# ipro7 register map
Vendor: intelpro; Series: BTBLE
CPU: ipro7, little endian
Registers are 32-bit, read-write, reset 0x0 unless marked. A register's access mark holds for its fields unless they carry their own. Offsets are from the block's base; [hi:lo] are bit positions; {n}, {i} and the like mark numbered series.

## M154_AES
Base 0x3C001000
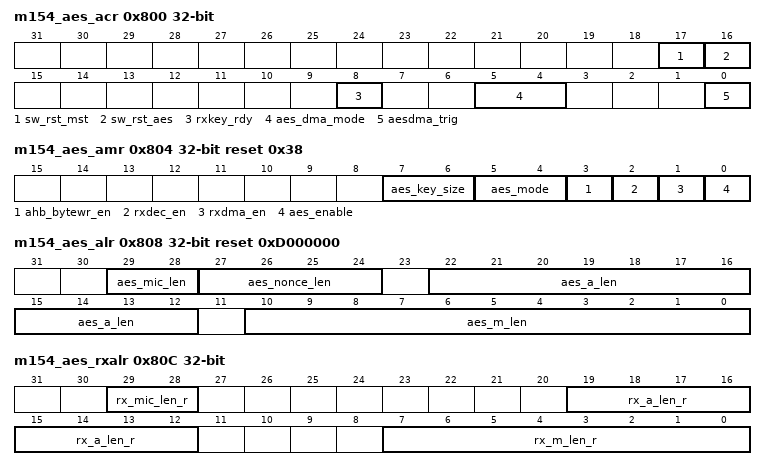
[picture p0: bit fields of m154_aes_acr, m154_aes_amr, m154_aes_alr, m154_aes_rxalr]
0x800 m154_aes_acr — AES control
  [17] sw_rst_mst — reset DDT master engine
  [16] sw_rst_aes — reset AES engine
  [8] rxkey_rdy — Validate key materials after key lookup complete
  [5:4] aes_dma_mode — 0 : FW mode encryption 1 : FW mode decryption 2 : HW mode TX DMA with encryption 3 : HW mode TX DMA without encryption
  [0] aesdma_trig — AES start
0x804 m154_aes_amr reset 0x38 — AES mode
  [7:6] aes_key_size — 0 : AES-128 1 : AES-192 2 : AES-256
  [5:4] aes_mode — 0 : AES Bypass mode : Bypass mode 1 : AES-CTR mode : Counter mode 2 : AES-CBC-MAC mode : Cipher Block Chaining Message Authentication Code mode 3 : AES-CCM mode : Counter with CBC-MAC
  [3] ahb_bytewr_en — Enable byte-write function
  [2] rxdec_en — Enable RX decryption function
  [1] rxdma_en — Enable RX DMA function
  [0] aes_enable — Enable AES and DMA state machine and clock.
0x808 m154_aes_alr reset 0xD000000 — AES length
  [29:28] aes_mic_len — AES Len = 4 / 8 / 16 / 12 bytes. Set 0 for AES Bypass mode.
  [27:24] aes_nonce_len — Nonce length (Byte) for CMAC/CCM mode. Value 11~14. Set 0 for AES Bypass mode.
  [22:12] aes_a_len — Additional authentication data length (Byte) or length of MPDU without FCS in AES Bypass mode
  [10:0] aes_m_len — Message length (Byte). Set 0 for CMAC mode and Bypass mode.
0x80C m154_aes_rxalr (reset mask 0xCFF00F00) — AES RX length
  [29:28] rx_mic_len_r ro — AES RX Len = 4 / 8 / 16 / 12 bytes. Valid in RX mode. Nonce length is always 13 bytes for CTR/CMAC/CCM mode
  [19:12] rx_a_len_r ro — The total length in byte of the additional authentication data, valid in RX mode
  [7:0] rx_m_len_r ro — The total length in byte of the message, valid in RX mode
0x810 m154_aes_aasar — AES a data source address
  [31:0] aes_asa — The source address of the Additional Authentication Data (a data) to be processed
0x814 m154_aes_amsar — AES m data source address
  [31:0] aes_msa — The source address of the encrypted or decrypted Message (m data)
0x818 m154_aes_amdar — AES m data destination address
  [31:0] aes_mda — The destination address of the encrypted or decrypted Message (c data)
0x81C m154_aes_rxaadar — AES RX a data destination address
  [31:0] aes_rxada — The destination address of the Additional Authentication Data (a data) to be processed in RX mode
0x820 m154_aes_rxamdar — AES RX m data destination address
  [31:0] aes_rxmda — The destination address of the decrypted Message (m data) in RX mode
0x830 m154_aes_anr0 — AES nonce
  [31:0] anr0 — Nonce field : Source Address({anr1[31:0], anr0[31:0]}), Frame Counter(anr2[31:0]), Security Level(anr3[7:0]) {anr2[23:0], anr1[31:0], anr0[31:0]} @aes_nonce_len=11 {anr2[31:0], anr1[31:0], anr0[31:0]} @aes_nonce_len=12 {anr3[7:0], anr2[31:0], anr1[31:0], anr0[31:0]} @aes_nonce_len=13 {anr3[15:0], anr2[31:0], anr1[31:0], anr0[31:0]} @aes_nonce_len=14
0x834 m154_aes_anr1
0x838 m154_aes_anr2
0x83C m154_aes_anr3
  [15:0] anr3
0x840 m154_aes_akr0 — AES key
  [31:0] akr0 — Key field {akr3, akr2, akr1, akr0} @AES-128 {akr5, akr4, akr3, akr2, akr1, akr0} @AES-192 {akr7, akr6, akr5, akr4, akr3, akr2, akr1, akr0} @AES-256
{0x840+4i} m154_aes_akr{i} (i=1..7)
0x860 m154_aes_amicr0 reset not defined — AES mic
  [31:0] amicr0 ro — Calculated MIC for CMAC/CCM, {amicr3, amicr2, amicr1, amicr0} depend on aes_mic_len
{0x860+4i} m154_aes_amicr{i} reset not defined (i=1..3)
  [31:0] amicr{i} ro
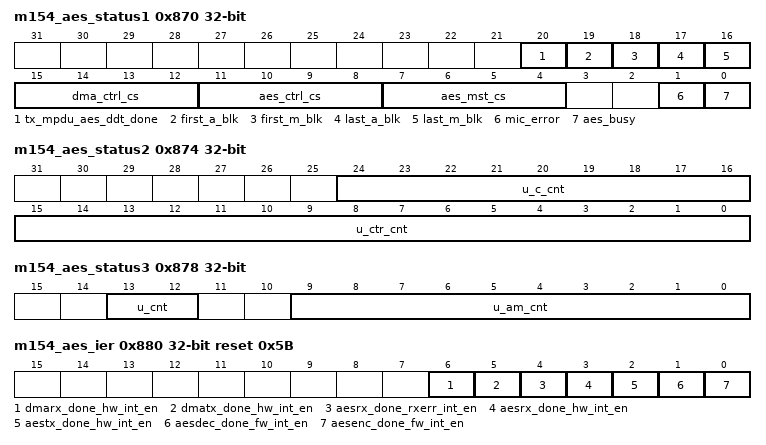
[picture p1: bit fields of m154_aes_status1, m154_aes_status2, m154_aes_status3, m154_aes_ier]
0x870 m154_aes_status1 (reset mask 0xFFE0000C) — AES status 1
  [20] tx_mpdu_aes_ddt_done ro
  [19] first_a_blk ro
  [18] first_m_blk ro
  [17] last_a_blk ro
  [16] last_m_blk ro
  [15:12] dma_ctrl_cs ro
  [11:8] aes_ctrl_cs ro
  [7:4] aes_mst_cs ro
  [1] mic_error ro — It means the MIC has been verified and checked passed
  [0] aes_busy ro — AES are busy processing
0x874 m154_aes_status2 (reset mask 0xFE000000) — AES status 2
  [24:16] u_c_cnt ro, [15:0] u_ctr_cnt ro
0x878 m154_aes_status3 (reset mask 0xFFFFCC00) — AES status 3
  [13:12] u_cnt ro, [9:0] u_am_cnt ro
0x880 m154_aes_ier reset 0x5B — Interrupt enable
  [6] dmarx_done_hw_int_en — Hardware mode RX DMA without decryption done interrupt enable
  [5] dmatx_done_hw_int_en — Hardware mode TX DMA without encryption done interrupt enable
  [4] aesrx_done_rxerr_int_en — AES hardware mode RX DMA decryption done with MIC error interrupt enable
  [3] aesrx_done_hw_int_en — AES hardware mode RX DMA done interrupt enable
  [2] aestx_done_hw_int_en — AES hardware mode TX DMA done interrupt enable
  [1] aesdec_done_fw_int_en — AES firmware mode decryption done enable
  [0] aesenc_done_fw_int_en — AES firmware mode encryption done enable
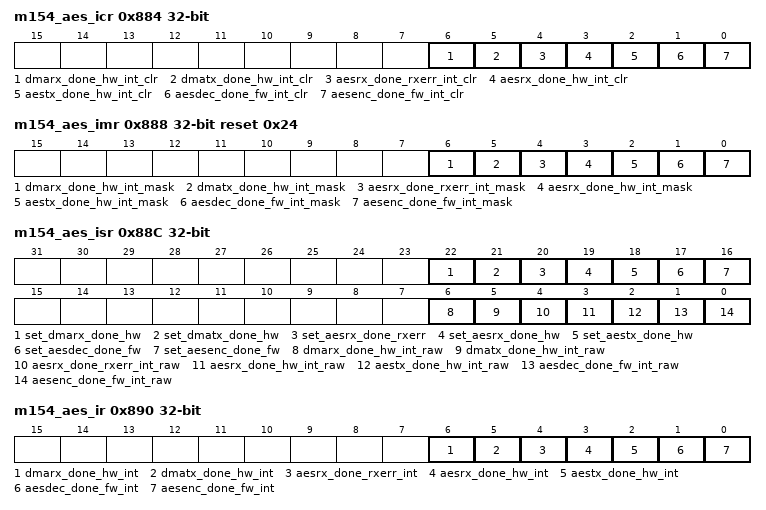
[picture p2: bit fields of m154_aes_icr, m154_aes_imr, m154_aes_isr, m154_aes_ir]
0x884 m154_aes_icr — Interrupt clear
  [6] dmarx_done_hw_int_clr — Hardware mode RX DMA without decryption done interrupt clear
  [5] dmatx_done_hw_int_clr — Hardware mode TX DMA without encryption done interrupt clear
  [4] aesrx_done_rxerr_int_clr — AES hardware mode RX DMA decryption done with MIC error interrupt clear
  [3] aesrx_done_hw_int_clr — AES hardware mode RX DMA done interrupt clear
  [2] aestx_done_hw_int_clr — AES hardware mode TX DMA done interrupt clear
  [1] aesdec_done_fw_int_clr — AES firmware mode decryption done interrupt clear
  [0] aesenc_done_fw_int_clr — AES firmware mode encryption done interrupt clear
0x888 m154_aes_imr reset 0x24 — Interrupt mask
  [6] dmarx_done_hw_int_mask — Hardware mode RX DMA without decryption done interrupt mask
  [5] dmatx_done_hw_int_mask — Hardware mode TX DMA without encryption done interrupt mask
  [4] aesrx_done_rxerr_int_mask — AES hardware mode RX DMA decryption done with MIC error interrupt mask
  [3] aesrx_done_hw_int_mask — AES hardware mode RX DMA done interrupt mask
  [2] aestx_done_hw_int_mask — AES hardware mode TX DMA done interrupt mask
  [1] aesdec_done_fw_int_mask — AES firmware mode decryption done interrupt mask
  [0] aesenc_done_fw_int_mask — AES firmware mode encryption done interrupt mask
0x88C m154_aes_isr (reset mask 0xFF80FF80) — Interrupt status
  [22] set_dmarx_done_hw ro
  [21] set_dmatx_done_hw ro
  [20] set_aesrx_done_rxerr ro
  [19] set_aesrx_done_hw ro
  [18] set_aestx_done_hw ro
  [17] set_aesdec_done_fw ro
  [16] set_aesenc_done_fw ro
  [6] dmarx_done_hw_int_raw ro — Hardware mode RX DMA without decryption done interrupt raw
  [5] dmatx_done_hw_int_raw ro — Hardware mode TX DMA without encryption done interrupt raw
  [4] aesrx_done_rxerr_int_raw ro — AES hardware mode RX DMA decryption done with MIC error interrupt raw
  [3] aesrx_done_hw_int_raw ro — AES hardware mode RX DMA done interrupt raw
  [2] aestx_done_hw_int_raw ro — AES hardware mode TX DMA done interrupt raw
  [1] aesdec_done_fw_int_raw ro — AES firmware mode decryption done interrupt raw
  [0] aesenc_done_fw_int_raw ro — AES firmware mode encryption done interrupt raw
0x890 m154_aes_ir (reset mask 0xFFFFFF80) — Interrupt
  [6] dmarx_done_hw_int ro — Hardware mode RX DMA without decryption done interrupt
  [5] dmatx_done_hw_int ro — Hardware mode TX DMA without encryption done interrupt
  [4] aesrx_done_rxerr_int ro — AES hardware mode RX DMA decryption done with MIC error interrupt
  [3] aesrx_done_hw_int ro — AES hardware mode RX DMA done interrupt
  [2] aestx_done_hw_int ro — AES hardware mode TX DMA done interrupt
  [1] aesdec_done_fw_int ro — AES firmware mode decryption done interrupt
  [0] aesenc_done_fw_int ro — AES firmware mode encryption done interrupt
